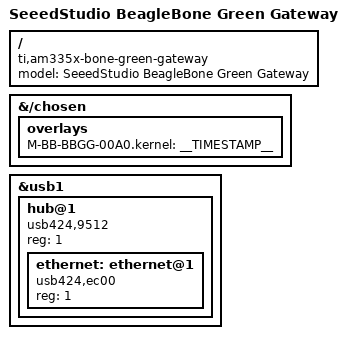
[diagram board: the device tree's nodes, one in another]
// SPDX-License-Identifier: GPL-2.0-only
/*
 * Copyright (C) 2012 Texas Instruments Incorporated - https://www.ti.com/
 */

/dts-v1/;
/plugin/;

#include <dt-bindings/gpio/gpio.h>
#include <dt-bindings/pinctrl/am33xx.h>
#include <dt-bindings/interrupt-controller/irq.h>

/*
 * Helper to show loaded overlays under: /proc/device-tree/chosen/overlays/
 */
&{/chosen} {
	overlays {
		M-BB-BBGG-00A0.kernel = __TIMESTAMP__;
	};
};

/ {
	fragment@0 {
		target-path="/";
		__overlay__ {
			model = "SeeedStudio BeagleBone Green Gateway";
			compatible = "ti,am335x-bone-green-gateway", "ti,am335x-bone-green", "ti,am335x-bone-black", "ti,am335x-bone", "ti,am33xx";
		};
	};

	fragment@8 {
		target = <&usb1>;
		__overlay__ {
			#address-cells = <1>;
			#size-cells = <0>;

			hub@1 {
				compatible = "usb424,9512";
				reg = <1>;
				#address-cells = <1>;
				#size-cells = <0>;

				ethernet: ethernet@1 {
					compatible = "usb424,ec00";
					reg = <1>;
				};
			};
		};
	};
};
